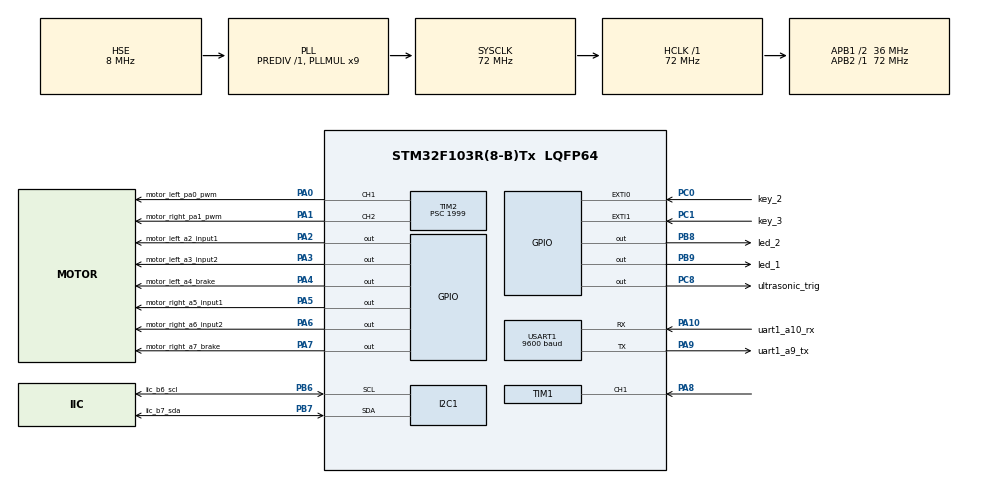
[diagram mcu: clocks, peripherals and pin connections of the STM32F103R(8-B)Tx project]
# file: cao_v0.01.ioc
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I2C1.I2C_Mode=I2C_Fast
I2C1.OwnAddress=0x0A
Mcu.Family=STM32F1
Mcu.Name=STM32F103R(8-B)Tx
Mcu.Package=LQFP64
NVIC.EXTI0_IRQn=true\:1\:0\:true\:false\:true\:true\:true
NVIC.EXTI1_IRQn=true\:1\:0\:true\:false\:true\:true\:true
NVIC.PriorityGroup=NVIC_PRIORITYGROUP_4
NVIC.TIM1_CC_IRQn=true\:2\:0\:true\:false\:true\:true\:true
NVIC.TIM1_UP_IRQn=true\:2\:0\:true\:false\:true\:true\:true
NVIC.USART1_IRQn=true\:0\:0\:false\:false\:true\:true\:true
PA0-WKUP.GPIO_Label=motor_left_pa0_pwm
PA0-WKUP.GPIO_Speed=GPIO_SPEED_FREQ_HIGH
PA0-WKUP.Signal=S_TIM2_CH1_ETR
PA1.GPIO_Label=motor_right_pa1_pwm
PA1.GPIO_Speed=GPIO_SPEED_FREQ_HIGH
PA1.Signal=S_TIM2_CH2
PA10.GPIO_Label=uart1_a10_rx
PA10.Mode=Asynchronous
PA10.Signal=USART1_RX
PA13.Mode=Trace_Asynchronous_SW
PA13.Signal=SYS_JTMS-SWDIO
PA14.Mode=Trace_Asynchronous_SW
PA14.Signal=SYS_JTCK-SWCLK
PA2.GPIO_Label=motor_left_a2_input1
PA2.GPIO_PuPd=GPIO_PULLDOWN
PA2.Signal=GPIO_Output
PA3.GPIO_Label=motor_left_a3_input2
PA3.GPIO_ModeDefaultOutputPP=GPIO_MODE_OUTPUT_PP
PA3.GPIO_PuPd=GPIO_PULLDOWN
PA3.Signal=GPIO_Output
PA4.GPIO_Label=motor_left_a4_brake
PA4.GPIO_PuPd=GPIO_PULLDOWN
PA4.Signal=GPIO_Output
PA5.GPIO_Label=motor_right_a5_input1
PA5.GPIO_PuPd=GPIO_PULLDOWN
PA5.Signal=GPIO_Output
PA6.GPIO_Label=motor_right_a6_input2
PA6.GPIO_ModeDefaultOutputPP=GPIO_MODE_OUTPUT_PP
PA6.GPIO_PuPd=GPIO_PULLDOWN
PA6.Signal=GPIO_Output
PA7.GPIO_Label=motor_right_a7_brake
PA7.GPIO_PuPd=GPIO_PULLDOWN
PA7.Signal=GPIO_Output
PA8.Signal=S_TIM1_CH1
PA9.GPIO_Label=uart1_a9_tx
PA9.Mode=Asynchronous
PA9.Signal=USART1_TX
PB3.Mode=Trace_Asynchronous_SW
PB3.Signal=SYS_JTDO-TRACESWO
PB6.GPIO_Label=iic_b6_scl
PB6.Mode=I2C
PB6.Signal=I2C1_SCL
PB7.GPIO_Label=iic_b7_sda
PB7.Mode=I2C
PB7.Signal=I2C1_SDA
PB8.GPIO_Label=led_2
PB8.Signal=GPIO_Output
PB9.GPIO_Label=led_1
PB9.Signal=GPIO_Output
PC0.GPIO_Label=key_2
PC0.GPIO_ModeDefaultEXTI=GPIO_MODE_IT_FALLING
PC0.GPIO_PuPd=GPIO_PULLUP
PC0.Signal=GPXTI0
PC1.GPIO_Label=key_3
PC1.GPIO_ModeDefaultEXTI=GPIO_MODE_IT_FALLING
PC1.GPIO_PuPd=GPIO_PULLUP
PC1.Signal=GPXTI1
PC8.GPIO_Label=ultrasonic_trig
PC8.GPIO_PuPd=GPIO_PULLDOWN
PC8.Signal=GPIO_Output
PD0-OSC_IN.Mode=HSE-External-Oscillator
PD0-OSC_IN.Signal=RCC_OSC_IN
PD1-OSC_OUT.Mode=HSE-External-Oscillator
PD1-OSC_OUT.Signal=RCC_OSC_OUT
ProjectManager.HeapSize=0x200
ProjectManager.StackSize=0x400
ProjectManager.TargetToolchain=MDK-ARM V5.32
RCC.AHBFreq_Value=72000000
RCC.APB1CLKDivider=RCC_HCLK_DIV2
RCC.APB1Freq_Value=36000000
RCC.APB1TimFreq_Value=72000000
RCC.APB2Freq_Value=72000000
RCC.APB2TimFreq_Value=72000000
RCC.HCLKFreq_Value=72000000
RCC.PLLMUL=RCC_PLL_MUL9
RCC.PLLSourceVirtual=RCC_PLLSOURCE_HSE
RCC.SYSCLKFreq_VALUE=72000000
RCC.SYSCLKSource=RCC_SYSCLKSOURCE_PLLCLK
RCC.USBFreq_Value=72000000
SH.S_TIM1_CH1.0=TIM1_CH1,Input_Capture1_from_TI1
SH.S_TIM2_CH1_ETR.0=TIM2_CH1,PWM Generation1 CH1
SH.S_TIM2_CH2.0=TIM2_CH2,PWM Generation2 CH2
TIM1.Channel-Input_Capture1_from_TI1=TIM_CHANNEL_1
TIM1.ICFilter_CH1=1
TIM1.Prescaler=71
TIM2.Channel-PWM\ Generation1\ CH1=TIM_CHANNEL_1
TIM2.Channel-PWM\ Generation2\ CH2=TIM_CHANNEL_2
TIM2.Period=255
TIM2.Prescaler=1999
USART1.BaudRate=9600
USART1.VirtualMode=VM_ASYNC
board=custom

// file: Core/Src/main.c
/* USER CODE BEGIN Header */
/**
  ******************************************************************************
  * @file           : main.c
  * @brief          : Main program body
  ******************************************************************************
  * @attention
  *
  * <h2><center>&copy; Copyright (c) 2022 STMicroelectronics.
  * All rights reserved.</center></h2>
  *
  * This software component is licensed by ST under BSD 3-Clause license,
  * the "License"; You may not use this file except in compliance with the
  * License. You may obtain a copy of the License at:
  *                        opensource.org/licenses/BSD-3-Clause
  *
  ******************************************************************************
  */
/* USER CODE END Header */
#include "main.h"
#include "i2c.h"
#include "tim.h"
#include "usart.h"
#include "gpio.h"

/* USER CODE BEGIN Includes */
#include "../../User/inc/cao_task.h"
#include "../../User/inc/cao_mpu.h"
#include "../../User/inc/cao_motor.h"
#include "../../User/inc/cao_ultrasonic.h"

/* USER CODE END Includes */

void SystemClock_Config(void);

int main(void)
{

  /* MCU Configuration--------------------------------------------------------*/

  /* Reset of all peripherals, Initializes the Flash interface and the Systick. */
  HAL_Init();

  /* Configure the system clock */
  SystemClock_Config();

  /* Initialize all configured peripherals */
  MX_GPIO_Init();
  MX_USART1_UART_Init();
  MX_I2C1_Init();
  MX_TIM2_Init();
  MX_TIM1_Init();
  /* USER CODE BEGIN 2 */
	HAL_UART_Receive_IT(&huart1, rx_buff, 1);
	capture_init();
  /* USER CODE END 2 */

  /* Infinite loop */
  while (1)
  {
		ultrasonic_measure();
		HAL_Delay(300);
  }
}

void SystemClock_Config(void)
{
  RCC_OscInitTypeDef RCC_OscInitStruct = {0};
  RCC_ClkInitTypeDef RCC_ClkInitStruct = {0};

  /** Initializes the RCC Oscillators according to the specified parameters
  * in the RCC_OscInitTypeDef structure.
  */
  RCC_OscInitStruct.OscillatorType = RCC_OSCILLATORTYPE_HSE;
  RCC_OscInitStruct.HSEState = RCC_HSE_ON;
  RCC_OscInitStruct.HSEPredivValue = RCC_HSE_PREDIV_DIV1;
  RCC_OscInitStruct.HSIState = RCC_HSI_ON;
  RCC_OscInitStruct.PLL.PLLState = RCC_PLL_ON;
  RCC_OscInitStruct.PLL.PLLSource = RCC_PLLSOURCE_HSE;
  RCC_OscInitStruct.PLL.PLLMUL = RCC_PLL_MUL9;
  if (HAL_RCC_OscConfig(&RCC_OscInitStruct) != HAL_OK)
  {
    Error_Handler();
  }
  /** Initializes the CPU, AHB and APB buses clocks
  */
  RCC_ClkInitStruct.ClockType = RCC_CLOCKTYPE_HCLK|RCC_CLOCKTYPE_SYSCLK
                              |RCC_CLOCKTYPE_PCLK1|RCC_CLOCKTYPE_PCLK2;
  RCC_ClkInitStruct.SYSCLKSource = RCC_SYSCLKSOURCE_PLLCLK;
  RCC_ClkInitStruct.AHBCLKDivider = RCC_SYSCLK_DIV1;
  RCC_ClkInitStruct.APB1CLKDivider = RCC_HCLK_DIV2;
  RCC_ClkInitStruct.APB2CLKDivider = RCC_HCLK_DIV1;

  if (HAL_RCC_ClockConfig(&RCC_ClkInitStruct, FLASH_LATENCY_2) != HAL_OK)
  {
    Error_Handler();
  }
}

void Error_Handler(void)
{
  __disable_irq();
  while (1)
  {
  }
}

/************************ (C) COPYRIGHT STMicroelectronics *****END OF FILE****/
